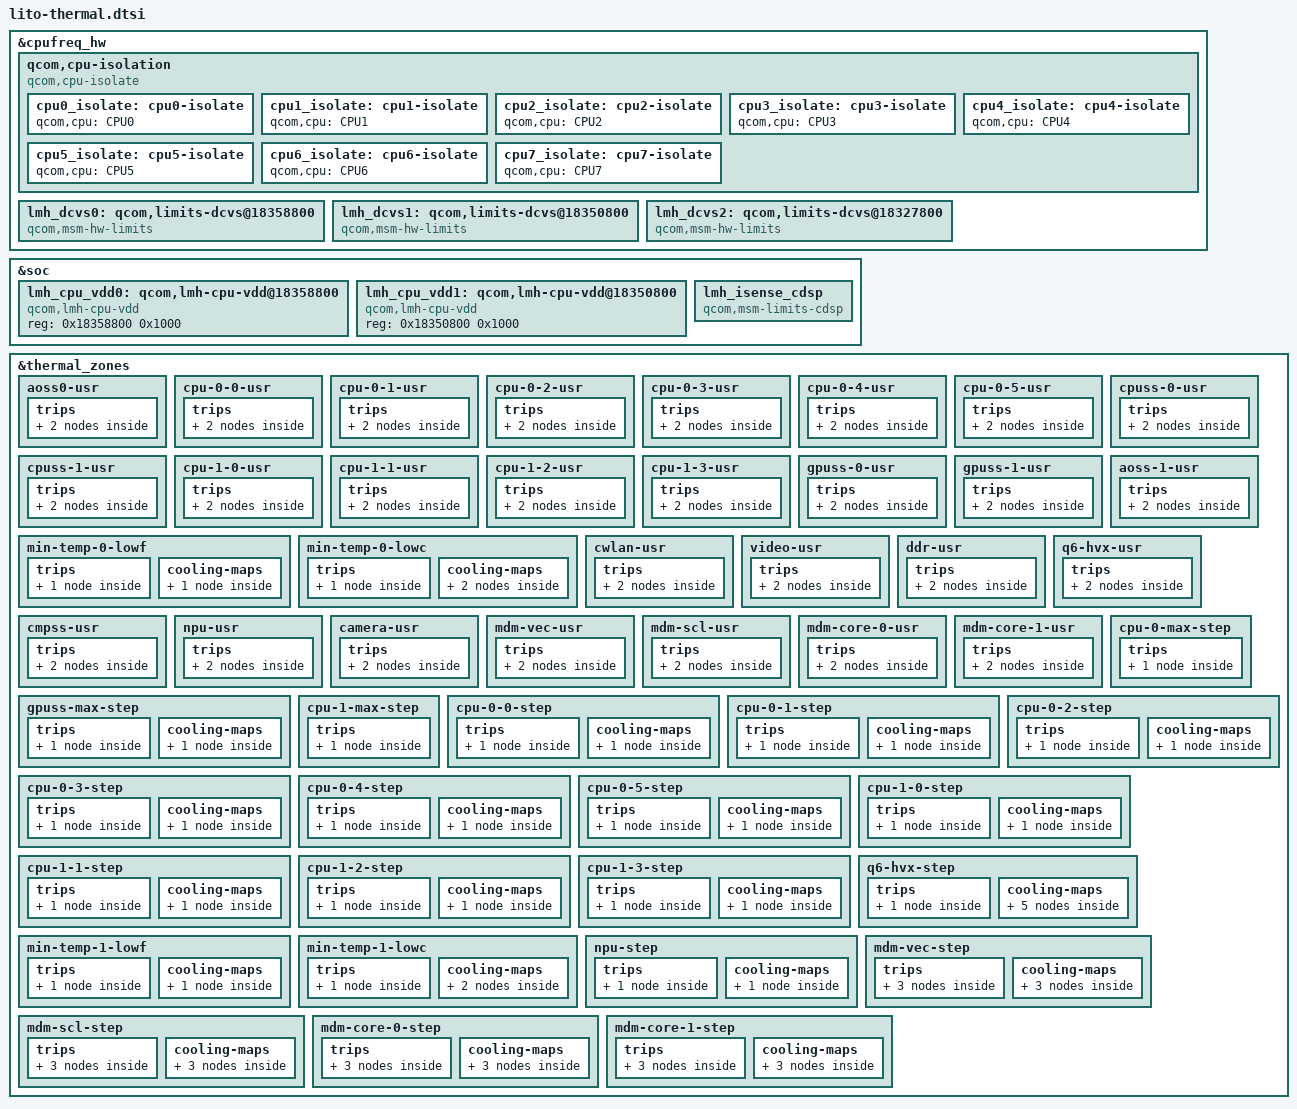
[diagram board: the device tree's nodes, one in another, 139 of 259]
#include <dt-bindings/thermal/thermal.h>
#include "sdxprairie-thermal-integrated.dtsi"

&cpufreq_hw {
	#address-cells = <1>;
	#size-cells = <1>;
	qcom,cpu-isolation {
		compatible = "qcom,cpu-isolate";
		cpu0_isolate: cpu0-isolate {
			qcom,cpu = <&CPU0>;
			#cooling-cells = <2>;
		};

		cpu1_isolate: cpu1-isolate {
			qcom,cpu = <&CPU1>;
			#cooling-cells = <2>;
		};

		cpu2_isolate: cpu2-isolate {
			qcom,cpu = <&CPU2>;
			#cooling-cells = <2>;
		};

		cpu3_isolate: cpu3-isolate {
			qcom,cpu = <&CPU3>;
			#cooling-cells = <2>;
		};

		cpu4_isolate: cpu4-isolate {
			qcom,cpu = <&CPU4>;
			#cooling-cells = <2>;
		};

		cpu5_isolate: cpu5-isolate {
			qcom,cpu = <&CPU5>;
			#cooling-cells = <2>;
		};

		cpu6_isolate: cpu6-isolate {
			qcom,cpu = <&CPU6>;
			#cooling-cells = <2>;
		};

		cpu7_isolate: cpu7-isolate {
			qcom,cpu = <&CPU7>;
			#cooling-cells = <2>;
		};
	};

	lmh_dcvs0: qcom,limits-dcvs@18358800 {
		compatible = "qcom,msm-hw-limits";
		interrupts = <GIC_SPI 32 IRQ_TYPE_LEVEL_HIGH>;
		qcom,affinity = <0>;
		reg = <0x18358800 0x1000>,
			<0x18323000 0x1000>;
		qcom,no-cooling-device-register;
		#thermal-sensor-cells = <0>;
	};

	lmh_dcvs1: qcom,limits-dcvs@18350800 {
		compatible = "qcom,msm-hw-limits";
		interrupts = <GIC_SPI 33 IRQ_TYPE_LEVEL_HIGH>;
		qcom,affinity = <1>;
		reg = <0x18350800 0x1000>,
			<0x18325800 0x1000>;
		qcom,no-cooling-device-register;
		#thermal-sensor-cells = <0>;
	};

	lmh_dcvs2: qcom,limits-dcvs@18327800 {
		compatible = "qcom,msm-hw-limits";
		interrupts = <GIC_SPI 33 IRQ_TYPE_LEVEL_HIGH>;
		qcom,affinity = <1>;
		reg = <0x18350800 0x1000>,
			<0x18327800 0x1000>;
		qcom,no-cooling-device-register;
		#thermal-sensor-cells = <0>;
	};
};

&soc {
	lmh_cpu_vdd0: qcom,lmh-cpu-vdd@18358800 {
		compatible = "qcom,lmh-cpu-vdd";
		reg =  <0x18358800 0x1000>;
		#cooling-cells = <2>;
	};

	lmh_cpu_vdd1: qcom,lmh-cpu-vdd@18350800 {
		compatible = "qcom,lmh-cpu-vdd";
		reg =  <0x18350800 0x1000>;
		#cooling-cells = <2>;
	};

	lmh_isense_cdsp {
		compatible = "qcom,msm-limits-cdsp";
	};
};

&thermal_zones {
	aoss0-usr {
		polling-delay-passive = <0>;
		polling-delay = <0>;
		thermal-governor = "user_space";
		thermal-sensors = <&tsens0 0>;
		wake-capable-sensor;
		trips {
			active-config0 {
				temperature = <125000>;
				hysteresis = <1000>;
				type = "passive";
			};

			reset-mon-config {
				temperature = <115000>;
				hysteresis = <1000>;
				type = "passive";
			};
		};
	};

	cpu-0-0-usr {
		polling-delay-passive = <0>;
		polling-delay = <0>;
		thermal-governor = "user_space";
		thermal-sensors = <&tsens0 1>;
		wake-capable-sensor;
		trips {
			active-config0 {
				temperature = <125000>;
				hysteresis = <1000>;
				type = "passive";
			};

			reset-mon-config {
				temperature = <115000>;
				hysteresis = <1000>;
				type = "passive";
			};
		};
	};

	cpu-0-1-usr {
		polling-delay-passive = <0>;
		polling-delay = <0>;
		thermal-governor = "user_space";
		thermal-sensors = <&tsens0 2>;
		wake-capable-sensor;
		trips {
			active-config0 {
				temperature = <125000>;
				hysteresis = <1000>;
				type = "passive";
			};

			reset-mon-config {
				temperature = <115000>;
				hysteresis = <1000>;
				type = "passive";
			};
		};
	};

	cpu-0-2-usr {
		polling-delay-passive = <0>;
		polling-delay = <0>;
		thermal-governor = "user_space";
		thermal-sensors = <&tsens0 3>;
		wake-capable-sensor;
		trips {
			active-config0 {
				temperature = <125000>;
				hysteresis = <1000>;
				type = "passive";
			};

			reset-mon-config {
				temperature = <115000>;
				hysteresis = <1000>;
				type = "passive";
			};
		};
	};

	cpu-0-3-usr {
		polling-delay-passive = <0>;
		polling-delay = <0>;
		thermal-sensors = <&tsens0 4>;
		thermal-governor = "user_space";
		wake-capable-sensor;
		trips {
			active-config0 {
				temperature = <125000>;
				hysteresis = <1000>;
				type = "passive";
			};

			reset-mon-config {
				temperature = <115000>;
				hysteresis = <1000>;
				type = "passive";
			};
		};
	};

	cpu-0-4-usr {
		polling-delay-passive = <0>;
		polling-delay = <0>;
		thermal-sensors = <&tsens0 5>;
		thermal-governor = "user_space";
		wake-capable-sensor;
		trips {
			active-config0 {
				temperature = <125000>;
				hysteresis = <1000>;
				type = "passive";
			};

			reset-mon-config {
				temperature = <115000>;
				hysteresis = <1000>;
				type = "passive";
			};
		};
	};

	cpu-0-5-usr {
		polling-delay-passive = <0>;
		polling-delay = <0>;
		thermal-sensors = <&tsens0 6>;
		thermal-governor = "user_space";
		wake-capable-sensor;
		trips {
			active-config0 {
				temperature = <125000>;
				hysteresis = <1000>;
				type = "passive";
			};

			reset-mon-config {
				temperature = <115000>;
				hysteresis = <1000>;
				type = "passive";
			};
		};
	};

	cpuss-0-usr {
		polling-delay-passive = <0>;
		polling-delay = <0>;
		thermal-sensors = <&tsens0 7>;
		thermal-governor = "user_space";
		wake-capable-sensor;
		trips {
			active-config0 {
				temperature = <125000>;
				hysteresis = <1000>;
				type = "passive";
			};

			reset-mon-config {
				temperature = <115000>;
				hysteresis = <1000>;
				type = "passive";
			};
		};
	};

	cpuss-1-usr {
		polling-delay-passive = <0>;
		polling-delay = <0>;
		thermal-sensors = <&tsens0 8>;
		thermal-governor = "user_space";
		wake-capable-sensor;
		trips {
			active-config0 {
				temperature = <125000>;
				hysteresis = <1000>;
				type = "passive";
			};

			reset-mon-config {
				temperature = <115000>;
				hysteresis = <1000>;
				type = "passive";
			};
		};
	};

	cpu-1-0-usr {
		polling-delay-passive = <0>;
		polling-delay = <0>;
		thermal-sensors = <&tsens0 9>;
		thermal-governor = "user_space";
		wake-capable-sensor;
		trips {
			active-config0 {
				temperature = <125000>;
				hysteresis = <1000>;
				type = "passive";
			};

			reset-mon-config {
				temperature = <115000>;
				hysteresis = <1000>;
				type = "passive";
			};
		};
	};

	cpu-1-1-usr {
		polling-delay-passive = <0>;
		polling-delay = <0>;
		thermal-sensors = <&tsens0 10>;
		thermal-governor = "user_space";
		wake-capable-sensor;
		trips {
			active-config0 {
				temperature = <125000>;
				hysteresis = <1000>;
				type = "passive";
			};

			reset-mon-config {
				temperature = <115000>;
				hysteresis = <1000>;
				type = "passive";
			};
		};
	};

	cpu-1-2-usr {
		polling-delay-passive = <0>;
		polling-delay = <0>;
		thermal-sensors = <&tsens0 11>;
		thermal-governor = "user_space";
		wake-capable-sensor;
		trips {
			active-config0 {
				temperature = <125000>;
				hysteresis = <1000>;
				type = "passive";
			};

			reset-mon-config {
				temperature = <115000>;
				hysteresis = <1000>;
				type = "passive";
			};
		};
	};

	cpu-1-3-usr {
		polling-delay-passive = <0>;
		polling-delay = <0>;
		thermal-sensors = <&tsens0 12>;
		thermal-governor = "user_space";
		wake-capable-sensor;
		trips {
			active-config0 {
				temperature = <125000>;
				hysteresis = <1000>;
				type = "passive";
			};

			reset-mon-config {
				temperature = <115000>;
				hysteresis = <1000>;
				type = "passive";
			};
		};
	};

	gpuss-0-usr {
		polling-delay-passive = <0>;
		polling-delay = <0>;
		thermal-sensors = <&tsens0 13>;
		thermal-governor = "user_space";
		wake-capable-sensor;
		trips {
			active-config0 {
				temperature = <125000>;
				hysteresis = <1000>;
				type = "passive";
			};

			reset-mon-config {
				temperature = <115000>;
				hysteresis = <1000>;
				type = "passive";
			};
		};
	};

	gpuss-1-usr {
		polling-delay-passive = <0>;
		polling-delay = <0>;
		thermal-sensors = <&tsens0 14>;
		thermal-governor = "user_space";
		wake-capable-sensor;
		trips {
			active-config0 {
				temperature = <125000>;
				hysteresis = <1000>;
				type = "passive";
			};

			reset-mon-config {
				temperature = <115000>;
				hysteresis = <1000>;
				type = "passive";
			};
		};
	};

	min-temp-0-lowf {
		polling-delay-passive = <0>;
		polling-delay = <0>;
		thermal-sensors = <&tsens0 16>;
		thermal-governor = "low_limits_floor";
		wake-capable-sensor;
		tracks-low;
		trips {
			min_temp_0_lowf: active-config0 {
				temperature = <5000>;
				hysteresis = <5000>;
				type = "passive";
			};
		};

		cooling-maps {
			lpi_cx_vdd_cdev {
				trip = <&min_temp_0_lowf>;
				cooling-device = <&lpi_cx_cdev 0 0>;
			};
		};

	};

	min-temp-0-lowc {
		polling-delay-passive = <0>;
		polling-delay = <0>;
		thermal-sensors = <&tsens0 16>;
		thermal-governor = "low_limits_cap";
		wake-capable-sensor;
		tracks-low;
		trips {
			min_temp_0_lowc: active-config0 {
				temperature = <5000>;
				hysteresis = <5000>;
				type = "passive";
			};
		};

		cooling-maps {
			lmh_cpu0_cdev {
				trip = <&min_temp_0_lowc>;
				cooling-device = <&lmh_cpu_vdd0 1 1>;
			};

			lmh_cpu6_cdev {
				trip = <&min_temp_0_lowc>;
				cooling-device = <&lmh_cpu_vdd1 1 1>;
			};
		};
	};

	aoss-1-usr {
		polling-delay-passive = <0>;
		polling-delay = <0>;
		thermal-sensors = <&tsens1 0>;
		thermal-governor = "user_space";
		wake-capable-sensor;
		trips {
			active-config0 {
				temperature = <125000>;
				hysteresis = <1000>;
				type = "passive";
			};

			reset-mon-config {
				temperature = <115000>;
				hysteresis = <1000>;
				type = "passive";
			};
		};
	};

	cwlan-usr {
		polling-delay-passive = <0>;
		polling-delay = <0>;
		thermal-sensors = <&tsens1 1>;
		thermal-governor = "user_space";
		wake-capable-sensor;
		trips {
			active-config0 {
				temperature = <125000>;
				hysteresis = <1000>;
				type = "passive";
			};

			reset-mon-config {
				temperature = <115000>;
				hysteresis = <1000>;
				type = "passive";
			};
		};
	};

	video-usr {
		polling-delay-passive = <0>;
		polling-delay = <0>;
		thermal-sensors = <&tsens1 2>;
		thermal-governor = "user_space";
		wake-capable-sensor;
		trips {
			active-config0 {
				temperature = <125000>;
				hysteresis = <1000>;
				type = "passive";
			};

			reset-mon-config {
				temperature = <115000>;
				hysteresis = <1000>;
				type = "passive";
			};
		};
	};

	ddr-usr {
		polling-delay-passive = <0>;
		polling-delay = <0>;
		thermal-sensors = <&tsens1 3>;
		thermal-governor = "user_space";
		wake-capable-sensor;
		trips {
			active-config0 {
				temperature = <125000>;
				hysteresis = <1000>;
				type = "passive";
			};

			reset-mon-config {
				temperature = <115000>;
				hysteresis = <1000>;
				type = "passive";
			};
		};
	};

	q6-hvx-usr {
		polling-delay-passive = <0>;
		polling-delay = <0>;
		thermal-sensors = <&tsens1 4>;
		thermal-governor = "user_space";
		wake-capable-sensor;
		trips {
			active-config0 {
				temperature = <125000>;
				hysteresis = <1000>;
				type = "passive";
			};

			reset-mon-config {
				temperature = <115000>;
				hysteresis = <1000>;
				type = "passive";
			};
		};
	};

	cmpss-usr {
		polling-delay-passive = <0>;
		polling-delay = <0>;
		thermal-sensors = <&tsens1 5>;
		thermal-governor = "user_space";
		wake-capable-sensor;
		trips {
			active-config0 {
				temperature = <125000>;
				hysteresis = <1000>;
				type = "passive";
			};

			reset-mon-config {
				temperature = <115000>;
				hysteresis = <1000>;
				type = "passive";
			};
		};
	};

	npu-usr {
		polling-delay-passive = <0>;
		polling-delay = <0>;
		thermal-sensors = <&tsens1 6>;
		thermal-governor = "user_space";
		wake-capable-sensor;
		trips {
			active-config0 {
				temperature = <125000>;
				hysteresis = <1000>;
				type = "passive";
			};

			reset-mon-config {
				temperature = <115000>;
				hysteresis = <1000>;
				type = "passive";
			};
		};
	};

	camera-usr {
		polling-delay-passive = <0>;
		polling-delay = <0>;
		thermal-sensors = <&tsens1 7>;
		thermal-governor = "user_space";
		wake-capable-sensor;
		trips {
			active-config0 {
				temperature = <125000>;
				hysteresis = <1000>;
				type = "passive";
			};

			reset-mon-config {
				temperature = <115000>;
				hysteresis = <1000>;
				type = "passive";
			};
		};
	};

	mdm-vec-usr {
		polling-delay-passive = <0>;
		polling-delay = <0>;
		thermal-sensors = <&tsens1 8>;
		thermal-governor = "user_space";
		wake-capable-sensor;
		trips {
			active-config0 {
				temperature = <125000>;
				hysteresis = <1000>;
				type = "passive";
			};

			reset-mon-config {
				temperature = <115000>;
				hysteresis = <1000>;
				type = "passive";
			};
		};
	};

	mdm-scl-usr {
		polling-delay-passive = <0>;
		polling-delay = <0>;
		thermal-sensors = <&tsens1 9>;
		thermal-governor = "user_space";
		wake-capable-sensor;
		trips {
			active-config0 {
				temperature = <125000>;
				hysteresis = <1000>;
				type = "passive";
			};

			reset-mon-config {
				temperature = <115000>;
				hysteresis = <1000>;
				type = "passive";
			};
		};
	};

	mdm-core-0-usr {
		polling-delay-passive = <0>;
		polling-delay = <0>;
		thermal-sensors = <&tsens1 10>;
		thermal-governor = "user_space";
		wake-capable-sensor;
		trips {
			active-config0 {
				temperature = <125000>;
				hysteresis = <1000>;
				type = "passive";
			};

			reset-mon-config {
				temperature = <115000>;
				hysteresis = <1000>;
				type = "passive";
			};
		};
	};

	mdm-core-1-usr {
		polling-delay-passive = <0>;
		polling-delay = <0>;
		thermal-governor = "user_space";
		thermal-sensors = <&tsens1 11>;
		wake-capable-sensor;
		trips {
			active-config0 {
				temperature = <125000>;
				hysteresis = <1000>;
				type = "passive";
			};

			reset-mon-config {
				temperature = <115000>;
				hysteresis = <1000>;
				type = "passive";
			};
		};
	};

	gpuss-max-step {
		polling-delay-passive = <10>;
		polling-delay = <100>;
		thermal-governor = "step_wise";
		wake-capable-sensor;
		trips {
			gpu_trip0: gpu-trip0 {
				temperature = <95000>;
				hysteresis = <0>;
				type = "passive";
			};
		};

		cooling-maps {
			gpu_cdev {
				trip = <&gpu_trip0>;
				cooling-device = <&msm_gpu THERMAL_NO_LIMIT
							THERMAL_NO_LIMIT>;
			};
		};
	};

	cpu-0-max-step {
		polling-delay-passive = <0>;
		polling-delay = <0>;
		thermal-governor = "step_wise";
		wake-capable-sensor;
		trips {
			silver-trip {
				temperature = <120000>;
				hysteresis = <0>;
				type = "passive";
			};
		};
	};

	cpu-1-max-step {
		polling-delay-passive = <0>;
		polling-delay = <0>;
		thermal-governor = "step_wise";
		wake-capable-sensor;
		trips {
			gold-trip {
				temperature = <120000>;
				hysteresis = <0>;
				type = "passive";
			};
		};
	};

	cpu-0-0-step {
		polling-delay-passive = <0>;
		polling-delay = <0>;
		thermal-governor = "step_wise";
		thermal-sensors = <&tsens0 1>;
		wake-capable-sensor;
		trips {
			cpu00_config: cpu00-config {
				temperature = <110000>;
				hysteresis = <10000>;
				type = "passive";
			};
		};

		cooling-maps {
			cpu00_cdev {
				trip = <&cpu00_config>;
				cooling-device = <&cpu0_isolate 1 1>;
			};
		};
	};

	cpu-0-1-step {
		polling-delay-passive = <0>;
		polling-delay = <0>;
		thermal-governor = "step_wise";
		thermal-sensors = <&tsens0 2>;
		wake-capable-sensor;
		trips {
			cpu01_config: cpu01-config {
				temperature = <110000>;
				hysteresis = <10000>;
				type = "passive";
			};
		};

		cooling-maps {
			cpu01_cdev {
				trip = <&cpu01_config>;
				cooling-device = <&cpu1_isolate 1 1>;
			};
		};
	};

	cpu-0-2-step {
		polling-delay-passive = <0>;
		polling-delay = <0>;
		thermal-governor = "step_wise";
		thermal-sensors = <&tsens0 3>;
		wake-capable-sensor;
		trips {
			cpu02_config: cpu02-config {
				temperature = <110000>;
				hysteresis = <10000>;
				type = "passive";
			};
		};

		cooling-maps {
			cpu02_cdev {
				trip = <&cpu02_config>;
				cooling-device = <&cpu2_isolate 1 1>;
			};
		};
	};

	cpu-0-3-step {
		polling-delay-passive = <0>;
		polling-delay = <0>;
		thermal-sensors = <&tsens0 4>;
		thermal-governor = "step_wise";
		wake-capable-sensor;
		trips {
			cpu03_config: cpu03-config {
				temperature = <110000>;
				hysteresis = <10000>;
				type = "passive";
			};
		};

		cooling-maps {
			cpu03_cdev {
				trip = <&cpu03_config>;
				cooling-device = <&cpu3_isolate 1 1>;
			};
		};
	};

	cpu-0-4-step {
		polling-delay-passive = <0>;
		polling-delay = <0>;
		thermal-sensors = <&tsens0 5>;
		thermal-governor = "step_wise";
		wake-capable-sensor;
		trips {
			cpu04_config: cpu04-config {
				temperature = <110000>;
				hysteresis = <10000>;
				type = "passive";
			};
		};

		cooling-maps {
			cpu04_cdev {
				trip = <&cpu04_config>;
				cooling-device = <&cpu4_isolate 1 1>;
			};
		};
	};

	cpu-0-5-step {
		polling-delay-passive = <0>;
		polling-delay = <0>;
		thermal-sensors = <&tsens0 6>;
		thermal-governor = "step_wise";
		wake-capable-sensor;
		trips {
			cpu05_config: cpu05-config {
				temperature = <110000>;
				hysteresis = <10000>;
				type = "passive";
			};
		};

		cooling-maps {
			cpu05_cdev {
				trip = <&cpu05_config>;
				cooling-device = <&cpu5_isolate 1 1>;
			};
		};
	};

	cpu-1-0-step {
		polling-delay-passive = <0>;
		polling-delay = <0>;
		thermal-sensors = <&tsens0 9>;
		thermal-governor = "step_wise";
		wake-capable-sensor;
		trips {
			cpu10_config: cpu10-config {
				temperature = <110000>;
				hysteresis = <10000>;
				type = "passive";
			};
		};

		cooling-maps {
			cpu10_cdev {
				trip = <&cpu10_config>;
				cooling-device = <&cpu6_isolate 1 1>;
			};
		};
	};

	cpu-1-1-step {
		polling-delay-passive = <0>;
		polling-delay = <0>;
		thermal-sensors = <&tsens0 10>;
		thermal-governor = "step_wise";
		wake-capable-sensor;
		trips {
			cpu11_config: cpu11-config {
				temperature = <110000>;
				hysteresis = <10000>;
				type = "passive";
			};
		};

		cooling-maps {
			cpu11_cdev {
				trip = <&cpu11_config>;
				cooling-device = <&cpu7_isolate 1 1>;
			};
		};
	};

	cpu-1-2-step {
		polling-delay-passive = <0>;
		polling-delay = <0>;
		thermal-sensors = <&tsens0 11>;
		thermal-governor = "step_wise";
		wake-capable-sensor;
		trips {
			cpu12_config: cpu12-config {
				temperature = <110000>;
				hysteresis = <10000>;
				type = "passive";
			};
		};

		cooling-maps {
			cpu12_cdev {
				trip = <&cpu12_config>;
				cooling-device = <&cpu6_isolate 1 1>;
			};
		};
	};

	cpu-1-3-step {
		polling-delay-passive = <0>;
		polling-delay = <0>;
		thermal-sensors = <&tsens0 12>;
		thermal-governor = "step_wise";
		wake-capable-sensor;
		trips {
			cpu13_config: cpu13-config {
				temperature = <110000>;
				hysteresis = <10000>;
				type = "passive";
			};
		};

		cooling-maps {
			cpu13_cdev {
				trip = <&cpu13_config>;
				cooling-device = <&cpu7_isolate 1 1>;
			};
		};
	};

	q6-hvx-step {
		polling-delay-passive = <0>;
		polling-delay = <0>;
		thermal-sensors = <&tsens1 4>;
		thermal-governor = "step_wise";
		wake-capable-sensor;
		trips {
			q6_hvx_trip1: q6-hvx-trip1 {
				temperature = <100000>;
				hysteresis = <5000>;
				type = "passive";
			};
		};

		cooling-maps {
			cdsp-cdev1 {
				trip = <&q6_hvx_trip1>;
				cooling-device = <&msm_cdsp_rm 3 3>;
			};

			gpu-cdev {
				trip = <&q6_hvx_trip1>;
				cooling-device = <&msm_gpu (THERMAL_MAX_LIMIT-1)
							(THERMAL_MAX_LIMIT-1)>;
			};

			modem-pa-cdev {
				trip = <&q6_hvx_trip1>;
				cooling-device = <&modem_pa 3 3>;
			};

			modem-tj-cdev {
				trip = <&q6_hvx_trip1>;
				cooling-device = <&modem_tj 3 3>;
			};

			npu_cdev {
				trip = <&q6_hvx_trip1>;
				cooling-device = <&msm_npu THERMAL_MAX_LIMIT
							THERMAL_MAX_LIMIT>;
			};
		};
	};

	min-temp-1-lowf {
		polling-delay-passive = <0>;
		polling-delay = <0>;
		thermal-sensors = <&tsens1 16>;
		thermal-governor = "low_limits_floor";
		wake-capable-sensor;
		tracks-low;
		trips {
			min_temp_1_lowf: active-config0 {
				temperature = <5000>;
				hysteresis = <5000>;
				type = "passive";
			};
		};

		cooling-maps {
			lpi_cx_vdd_cdev {
				trip = <&min_temp_1_lowf>;
				cooling-device = <&lpi_cx_cdev 0 0>;
			};
		};
	};

	min-temp-1-lowc {
		polling-delay-passive = <0>;
		polling-delay = <0>;
		thermal-sensors = <&tsens1 16>;
		thermal-governor = "low_limits_cap";
		wake-capable-sensor;
		tracks-low;
		trips {
			min_temp_1_lowc: active-config0 {
				temperature = <5000>;
				hysteresis = <5000>;
				type = "passive";
			};
		};

		cooling-maps {
			lmh_cpu0_cdev {
				trip = <&min_temp_1_lowc>;
				cooling-device = <&lmh_cpu_vdd0 1 1>;
			};

			lmh_cpu6_cdev {
				trip = <&min_temp_1_lowc>;
				cooling-device = <&lmh_cpu_vdd1 1 1>;
			};
		};
	};

	npu-step {
		polling-delay-passive = <10>;
		polling-delay = <0>;
		thermal-sensors = <&tsens1 6>;
		thermal-governor = "step_wise";
		wake-capable-sensor;
		trips {
			npu_trip0: npu-trip0 {
				temperature = <95000>;
				hysteresis = <0>;
				type = "passive";
			};
		};

		cooling-maps {
			npu_cdev {
				trip = <&npu_trip0>;
				cooling-device =
					<&msm_npu THERMAL_NO_LIMIT
						THERMAL_NO_LIMIT>;
			};
		};
	};

	mdm-vec-step {
		polling-delay-passive = <0>;
		polling-delay = <0>;
		thermal-sensors = <&tsens1 8>;
		thermal-governor = "step_wise";
		wake-capable-sensor;
		trips {
			modem_vec_trip0: modem-vec-trip0 {
				temperature = <95000>;
				hysteresis = <15000>;
				type = "passive";
			};

			modem_vec_trip1: modem-vec-trip1 {
				temperature = <105000>;
				hysteresis = <15000>;
				type = "passive";
			};

			modem_vec_trip2: modem-vec-trip2 {
				temperature = <115000>;
				hysteresis = <15000>;
				type = "passive";
			};
		};

		cooling-maps {
			modem_tj1_cdev {
				trip = <&modem_vec_trip0>;
				cooling-device = <&modem_tj 1 1>;
			};

			modem_tj2_cdev {
				trip = <&modem_vec_trip1>;
				cooling-device = <&modem_tj 2 2>;
			};

			modem_tj3_cdev {
				trip = <&modem_vec_trip2>;
				cooling-device = <&modem_tj 3 3>;
			};
		};
	};

	mdm-scl-step {
		polling-delay-passive = <0>;
		polling-delay = <0>;
		thermal-sensors = <&tsens1 9>;
		thermal-governor = "step_wise";
		wake-capable-sensor;
		trips {
			modem_scl_trip0: modem-scl-trip0 {
				temperature = <95000>;
				hysteresis = <15000>;
				type = "passive";
			};

			modem_scl_trip1: modem-scl-trip1 {
				temperature = <105000>;
				hysteresis = <15000>;
				type = "passive";
			};

			modem_scl_trip2: modem-scl-trip2 {
				temperature = <115000>;
				hysteresis = <15000>;
				type = "passive";
			};
		};

		cooling-maps {
			modem_tj1_cdev {
				trip = <&modem_scl_trip0>;
				cooling-device = <&modem_tj 1 1>;
			};

			modem_tj2_cdev {
				trip = <&modem_scl_trip1>;
				cooling-device = <&modem_tj 2 2>;
			};

			modem_tj3_cdev {
				trip = <&modem_scl_trip2>;
				cooling-device = <&modem_tj 3 3>;
			};
		};
	};

	mdm-core-0-step {
		polling-delay-passive = <0>;
		polling-delay = <0>;
		thermal-sensors = <&tsens1 10>;
		thermal-governor = "step_wise";
		wake-capable-sensor;
		trips {
			modem_core_0_trip0: modem-core-0-trip0 {
				temperature = <95000>;
				hysteresis = <15000>;
				type = "passive";
			};

			modem_core_0_trip1: modem-core-0-trip1 {
				temperature = <105000>;
				hysteresis = <15000>;
				type = "passive";
			};

			modem_core_0_trip2: modem-core-0-trip2 {
				temperature = <115000>;
				hysteresis = <15000>;
				type = "passive";
			};
		};

		cooling-maps {
			modem_tj1_cdev {
				trip = <&modem_core_0_trip0>;
				cooling-device = <&modem_tj 1 1>;
			};

			modem_tj2_cdev {
				trip = <&modem_core_0_trip1>;
				cooling-device = <&modem_tj 2 2>;
			};

			modem_tj3_cdev {
				trip = <&modem_core_0_trip2>;
				cooling-device = <&modem_tj 3 3>;
			};
		};
	};

	mdm-core-1-step {
		polling-delay-passive = <0>;
		polling-delay = <0>;
		thermal-sensors = <&tsens1 11>;
		thermal-governor = "step_wise";
		wake-capable-sensor;
		trips {
			modem_core_1_trip0: modem-core-1-trip0 {
				temperature = <95000>;
				hysteresis = <15000>;
				type = "passive";
			};

			modem_core_1_trip1: modem-core-1-trip1 {
				temperature = <105000>;
				hysteresis = <15000>;
				type = "passive";
			};

			modem_core_1_trip2: modem-core-1-trip2 {
				temperature = <115000>;
				hysteresis = <15000>;
				type = "passive";
			};
		};

		cooling-maps {
			modem_tj1_cdev {
				trip = <&modem_core_1_trip0>;
				cooling-device = <&modem_tj 1 1>;
			};

			modem_tj2_cdev {
				trip = <&modem_core_1_trip1>;
				cooling-device = <&modem_tj 2 2>;
			};

			modem_tj3_cdev {
				trip = <&modem_core_1_trip2>;
				cooling-device = <&modem_tj 3 3>;
			};
		};
	};
};
